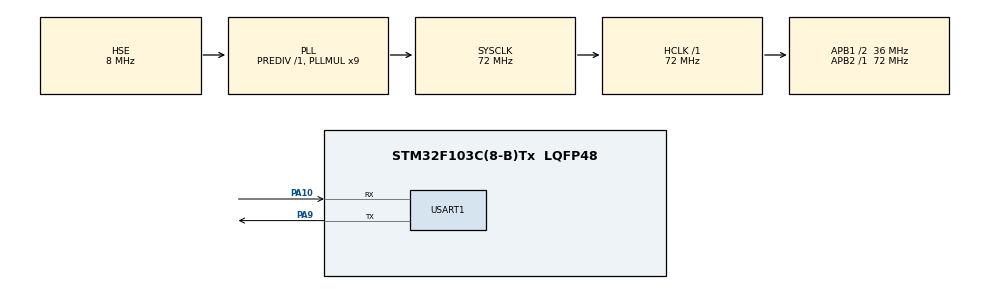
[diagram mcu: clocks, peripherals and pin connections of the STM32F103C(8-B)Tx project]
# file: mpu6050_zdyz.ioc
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Mcu.Family=STM32F1
Mcu.Name=STM32F103C(8-B)Tx
Mcu.Package=LQFP48
NVIC.PriorityGroup=NVIC_PRIORITYGROUP_4
PA10.Mode=Asynchronous
PA10.Signal=USART1_RX
PA13.Mode=Serial_Wire
PA13.Signal=SYS_JTMS-SWDIO
PA14.Mode=Serial_Wire
PA14.Signal=SYS_JTCK-SWCLK
PA9.Mode=Asynchronous
PA9.Signal=USART1_TX
PD0-OSC_IN.Mode=HSE-External-Oscillator
PD0-OSC_IN.Signal=RCC_OSC_IN
PD1-OSC_OUT.Mode=HSE-External-Oscillator
PD1-OSC_OUT.Signal=RCC_OSC_OUT
ProjectManager.HeapSize=0x200
ProjectManager.StackSize=0x400
ProjectManager.TargetToolchain=MDK-ARM V5.32
RCC.AHBFreq_Value=72000000
RCC.APB1CLKDivider=RCC_HCLK_DIV2
RCC.APB1Freq_Value=36000000
RCC.APB1TimFreq_Value=72000000
RCC.APB2Freq_Value=72000000
RCC.APB2TimFreq_Value=72000000
RCC.HCLKFreq_Value=72000000
RCC.PLLMUL=RCC_PLL_MUL9
RCC.PLLSourceVirtual=RCC_PLLSOURCE_HSE
RCC.SYSCLKFreq_VALUE=72000000
RCC.SYSCLKSource=RCC_SYSCLKSOURCE_PLLCLK
RCC.USBFreq_Value=72000000
USART1.VirtualMode=VM_ASYNC
board=custom

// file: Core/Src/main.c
/* USER CODE BEGIN Header */
/**
  ******************************************************************************
  * @file           : main.c
  * @brief          : Main program body
  ******************************************************************************
  * @attention
  *
  * Copyright (c) 2023 STMicroelectronics.
  * All rights reserved.
  *
  * This software is licensed under terms that can be found in the LICENSE file
  * in the root directory of this software component.
  * If no LICENSE file comes with this software, it is provided AS-IS.
  *
  ******************************************************************************
  */
/* USER CODE END Header */
#include "main.h"
#include "usart.h"
#include "gpio.h"

/* USER CODE BEGIN Includes */
#include "inv_mpu.h"
#include "atk_ms6050.h"

/* USER CODE END Includes */

/* USER CODE BEGIN PV */
  uint8_t ret;
    float pit, rol, yaw;
    int16_t acc_x, acc_y, acc_z;
    int16_t gyr_x, gyr_y, gyr_z;
    int16_t temp;
/* USER CODE END PV */

void SystemClock_Config(void);

int main(void)
{

  /* MCU Configuration--------------------------------------------------------*/

  /* Reset of all peripherals, Initializes the Flash interface and the Systick. */
  HAL_Init();

  /* Configure the system clock */
  SystemClock_Config();

  /* Initialize all configured peripherals */
  MX_GPIO_Init();
  MX_USART1_UART_Init();
  /* USER CODE BEGIN 2 */
   my_mpu6050_init ();
  /* USER CODE END 2 */

  /* Infinite loop */
  while (1)
  {

    /* USER CODE BEGIN 3 */

        /* 获取ATK-MS6050 DMP处理后的数据 */
        ret  = atk_ms6050_dmp_get_data(&pit, &rol, &yaw);
        /* 获取ATK-MS6050加速度值 */
        ret += atk_ms6050_get_accelerometer(&acc_x, &acc_y, &acc_z);
        /* 获取ATK-MS6050陀螺仪值 */
        ret += atk_ms6050_get_gyroscope(&gyr_x, &gyr_y, &gyr_z);
        /* 获取ATK-MS6050温度值 */
        ret += atk_ms6050_get_temperature(&temp);
        if (ret == 0)
        {
            if (1)
            {
                /* 上传相关数据信息至串口调试助手 */
                printf("pit: %.2f, rol: %.2f, yaw: %.2f, ", pit, rol, yaw);
                printf("acc_x: %d, acc_y: %d, acc_z: %d, ", acc_x, acc_y, acc_z);
                printf("gyr_x: %d, gyr_y: %d, gyr_z: %d, ", gyr_x, gyr_y, gyr_z);
                printf("temp: %d\r\n", temp);

            }

        }
  }
  /* USER CODE END 3 */
}

void SystemClock_Config(void)
{
  RCC_OscInitTypeDef RCC_OscInitStruct = {0};
  RCC_ClkInitTypeDef RCC_ClkInitStruct = {0};

  /** Initializes the RCC Oscillators according to the specified parameters
  * in the RCC_OscInitTypeDef structure.
  */
  RCC_OscInitStruct.OscillatorType = RCC_OSCILLATORTYPE_HSE;
  RCC_OscInitStruct.HSEState = RCC_HSE_ON;
  RCC_OscInitStruct.HSEPredivValue = RCC_HSE_PREDIV_DIV1;
  RCC_OscInitStruct.HSIState = RCC_HSI_ON;
  RCC_OscInitStruct.PLL.PLLState = RCC_PLL_ON;
  RCC_OscInitStruct.PLL.PLLSource = RCC_PLLSOURCE_HSE;
  RCC_OscInitStruct.PLL.PLLMUL = RCC_PLL_MUL9;
  if (HAL_RCC_OscConfig(&RCC_OscInitStruct) != HAL_OK)
  {
    Error_Handler();
  }

  /** Initializes the CPU, AHB and APB buses clocks
  */
  RCC_ClkInitStruct.ClockType = RCC_CLOCKTYPE_HCLK|RCC_CLOCKTYPE_SYSCLK
                              |RCC_CLOCKTYPE_PCLK1|RCC_CLOCKTYPE_PCLK2;
  RCC_ClkInitStruct.SYSCLKSource = RCC_SYSCLKSOURCE_PLLCLK;
  RCC_ClkInitStruct.AHBCLKDivider = RCC_SYSCLK_DIV1;
  RCC_ClkInitStruct.APB1CLKDivider = RCC_HCLK_DIV2;
  RCC_ClkInitStruct.APB2CLKDivider = RCC_HCLK_DIV1;

  if (HAL_RCC_ClockConfig(&RCC_ClkInitStruct, FLASH_LATENCY_2) != HAL_OK)
  {
    Error_Handler();
  }
}

void Error_Handler(void)
{
  __disable_irq();
  while (1)
  {
  }
}
